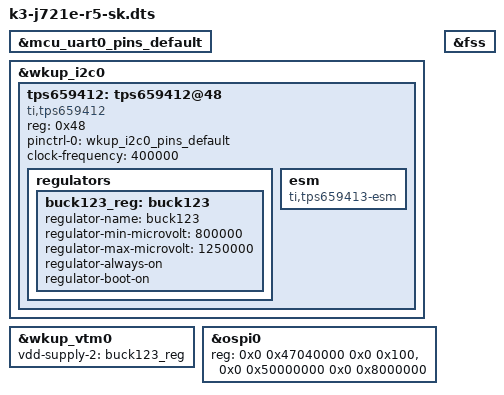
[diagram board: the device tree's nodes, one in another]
// SPDX-License-Identifier: GPL-2.0
/*
 * Copyright (C) 2021 Texas Instruments Incorporated - https://www.ti.com/
 */

/dts-v1/;

#include "k3-j721e-sk.dts"
#include "k3-j721e-ddr-sk-lp4-4266.dtsi"
#include "k3-j721e-ddr.dtsi"
#include "k3-j721e-sk-u-boot.dtsi"

#include "k3-j721e-r5.dtsi"

&mcu_uart0_pins_default {
	bootph-pre-ram;
};

&wkup_i2c0 {
	bootph-pre-ram;
	tps659412: tps659412@48 {
		reg = <0x48>;
		compatible = "ti,tps659412";
		bootph-pre-ram;
		pinctrl-names = "default";
		pinctrl-0 = <&wkup_i2c0_pins_default>;
		clock-frequency = <400000>;

		regulators: regulators {
			bootph-pre-ram;
			/* 3 Phase Buck */
			buck123_reg: buck123 {
				/* VDD_CPU */
				regulator-name = "buck123";
				regulator-min-microvolt = <800000>;
				regulator-max-microvolt = <1250000>;
				regulator-always-on;
				regulator-boot-on;
				bootph-pre-ram;
			};
		};

		esm: esm {
			compatible = "ti,tps659413-esm";
			bootph-pre-ram;
		};
	};
};

&wkup_vtm0 {
	vdd-supply-2 = <&buck123_reg>;
	bootph-pre-ram;
};

&ospi0 {
	/* Address change for data region (32-bit) */
	reg = <0x0 0x47040000 0x0 0x100>,
	      <0x0 0x50000000 0x0 0x8000000>;
};

&fss {
	/* enable ranges missing from the FSS node */
	ranges = <0x0 0x47000000 0x0 0x47000000 0x0 0x00068400>,
	         <0x0 0x50000000 0x0 0x50000000 0x0 0x08000000>;
};
